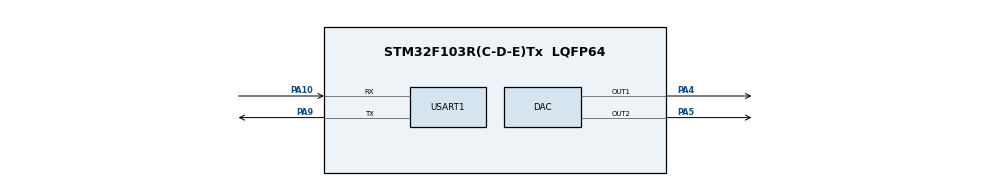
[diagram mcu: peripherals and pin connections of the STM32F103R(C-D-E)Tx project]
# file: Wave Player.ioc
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DAC.DAC_OutputBuffer=DAC_OUTPUTBUFFER_ENABLE
DAC.DAC_Trigger=DAC_TRIGGER_T2_TRGO
DAC.DAC_Trigger2=DAC_TRIGGER_T2_TRGO
Dma.DAC_CH1.0.Direction=DMA_MEMORY_TO_PERIPH
Dma.DAC_CH1.0.Instance=DMA2_Channel3
Dma.DAC_CH1.0.MemDataAlignment=DMA_MDATAALIGN_HALFWORD
Dma.DAC_CH1.0.MemInc=DMA_MINC_ENABLE
Dma.DAC_CH1.0.Mode=DMA_CIRCULAR
Dma.DAC_CH1.0.PeriphDataAlignment=DMA_PDATAALIGN_HALFWORD
Dma.DAC_CH1.0.PeriphInc=DMA_PINC_DISABLE
Dma.DAC_CH1.0.Priority=DMA_PRIORITY_MEDIUM
Dma.Request0=DAC_CH1
Mcu.Family=STM32F1
Mcu.Name=STM32F103R(C-D-E)Tx
Mcu.Package=LQFP64
NVIC.DMA2_Channel3_IRQn=true\:0\:0\:false\:false\:true\:false\:true
NVIC.PriorityGroup=NVIC_PRIORITYGROUP_4
PA10.Mode=Asynchronous
PA10.Signal=USART1_RX
PA13.Mode=JTAG_5_pins
PA13.Signal=SYS_JTMS-SWDIO
PA14.Mode=JTAG_5_pins
PA14.Signal=SYS_JTCK-SWCLK
PA15.Mode=JTAG_5_pins
PA15.Signal=SYS_JTDI
PA4.Signal=COMP_DAC1_group
PA5.Signal=COMP_DAC2_group
PA9.Mode=Asynchronous
PA9.Signal=USART1_TX
PB3.Mode=JTAG_5_pins
PB3.Signal=SYS_JTDO-TRACESWO
PB4.Mode=JTAG_5_pins
PB4.Signal=SYS_NJTRST
PD0-OSC_IN.Mode=HSE-External-Oscillator
PD0-OSC_IN.Signal=RCC_OSC_IN
PD1-OSC_OUT.Mode=HSE-External-Oscillator
PD1-OSC_OUT.Signal=RCC_OSC_OUT
ProjectManager.HeapSize=0x200
ProjectManager.StackSize=0x400
ProjectManager.TargetToolchain=MDK-ARM V5.27
RCC.AHBFreq_Value=72000000
RCC.APB1CLKDivider=RCC_HCLK_DIV2
RCC.APB1Freq_Value=36000000
RCC.APB1TimFreq_Value=72000000
RCC.APB2Freq_Value=72000000
RCC.APB2TimFreq_Value=72000000
RCC.HCLKFreq_Value=72000000
RCC.PLLMUL=RCC_PLL_MUL9
RCC.PLLSourceVirtual=RCC_PLLSOURCE_HSE
RCC.SYSCLKFreq_VALUE=72000000
RCC.SYSCLKSource=RCC_SYSCLKSOURCE_PLLCLK
RCC.USBFreq_Value=72000000
SH.COMP_DAC1_group.0=DAC_OUT1,DAC_OUT1
SH.COMP_DAC2_group.0=DAC_OUT2,DAC_OUT2
TIM2.Period=124
TIM2.Prescaler=7
TIM2.TIM_MasterOutputTrigger=TIM_TRGO_UPDATE
USART1.VirtualMode=VM_ASYNC
VP_TIM2_VS_ClockSourceINT.Mode=Internal
board=custom

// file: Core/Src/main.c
/* USER CODE BEGIN Header */
/**
  ******************************************************************************
  * @file           : main.c
  * @brief          : Main program body
  ******************************************************************************
  * @attention
  *
  * <h2><center>&copy; Copyright (c) 2022 STMicroelectronics.
  * All rights reserved.</center></h2>
  *
  * This software component is licensed by ST under BSD 3-Clause license,
  * the "License"; You may not use this file except in compliance with the
  * License. You may obtain a copy of the License at:
  *                        opensource.org/licenses/BSD-3-Clause
  *
  ******************************************************************************
  */
/* USER CODE END Header */
#include "main.h"

/* USER CODE BEGIN Includes */
#include "WAV_Handler.h"
/* USER CODE END Includes */

void SystemClock_Config(void);
static void MX_GPIO_Init(void);
static void MX_DMA_Init(void);
static void MX_DAC_Init(void);
static void MX_USART1_UART_Init(void);
static void MX_TIM2_Init(void);

int main(void)
{

  /* MCU Configuration--------------------------------------------------------*/

  /* Reset of all peripherals, Initializes the Flash interface and the Systick. */

  LL_APB2_GRP1_EnableClock(LL_APB2_GRP1_PERIPH_AFIO);
  LL_APB1_GRP1_EnableClock(LL_APB1_GRP1_PERIPH_PWR);

  NVIC_SetPriorityGrouping(NVIC_PRIORITYGROUP_4);

  /* System interrupt init*/

  /** ENABLE: Full SWJ (JTAG-DP + SW-DP): Reset State
  */
  LL_GPIO_AF_EnableRemap_SWJ();

  /* Configure the system clock */
  SystemClock_Config();

  /* Initialize all configured peripherals */
  MX_GPIO_Init();
  MX_DMA_Init();
  MX_DAC_Init();
  MX_USART1_UART_Init();
  MX_TIM2_Init();
  /* USER CODE BEGIN 2 */
	wave_Init();
	wave_play("Colors.wav");
  /* USER CODE END 2 */

  /* Infinite loop */
  while (1)
  {

  }
}

void SystemClock_Config(void)
{
  LL_FLASH_SetLatency(LL_FLASH_LATENCY_2);
  while(LL_FLASH_GetLatency()!= LL_FLASH_LATENCY_2)
  {
  }
  LL_RCC_HSE_Enable();

   /* Wait till HSE is ready */
  while(LL_RCC_HSE_IsReady() != 1)
  {

  }
  LL_RCC_PLL_ConfigDomain_SYS(LL_RCC_PLLSOURCE_HSE_DIV_1, LL_RCC_PLL_MUL_9);
  LL_RCC_PLL_Enable();

   /* Wait till PLL is ready */
  while(LL_RCC_PLL_IsReady() != 1)
  {

  }
  LL_RCC_SetAHBPrescaler(LL_RCC_SYSCLK_DIV_1);
  LL_RCC_SetAPB1Prescaler(LL_RCC_APB1_DIV_2);
  LL_RCC_SetAPB2Prescaler(LL_RCC_APB2_DIV_1);
  LL_RCC_SetSysClkSource(LL_RCC_SYS_CLKSOURCE_PLL);

   /* Wait till System clock is ready */
  while(LL_RCC_GetSysClkSource() != LL_RCC_SYS_CLKSOURCE_STATUS_PLL)
  {

  }
  LL_Init1msTick(72000000);
  LL_SetSystemCoreClock(72000000);
}

static void MX_DAC_Init(void)
{

  LL_DAC_InitTypeDef DAC_InitStruct = {0};

  LL_GPIO_InitTypeDef GPIO_InitStruct = {0};

  /* Peripheral clock enable */
  LL_APB1_GRP1_EnableClock(LL_APB1_GRP1_PERIPH_DAC1);

  LL_APB2_GRP1_EnableClock(LL_APB2_GRP1_PERIPH_GPIOA);
  /**DAC GPIO Configuration
  PA4   ------> DAC_OUT1
  PA5   ------> DAC_OUT2
  */
  GPIO_InitStruct.Pin = LL_GPIO_PIN_4|LL_GPIO_PIN_5;
  GPIO_InitStruct.Mode = LL_GPIO_MODE_ANALOG;
  LL_GPIO_Init(GPIOA, &GPIO_InitStruct);

  /* DAC DMA Init */

  /* DAC_CH1 Init */
  LL_DMA_SetDataTransferDirection(DMA2, LL_DMA_CHANNEL_3, LL_DMA_DIRECTION_MEMORY_TO_PERIPH);

  LL_DMA_SetChannelPriorityLevel(DMA2, LL_DMA_CHANNEL_3, LL_DMA_PRIORITY_MEDIUM);

  LL_DMA_SetMode(DMA2, LL_DMA_CHANNEL_3, LL_DMA_MODE_CIRCULAR);

  LL_DMA_SetPeriphIncMode(DMA2, LL_DMA_CHANNEL_3, LL_DMA_PERIPH_NOINCREMENT);

  LL_DMA_SetMemoryIncMode(DMA2, LL_DMA_CHANNEL_3, LL_DMA_MEMORY_INCREMENT);

  LL_DMA_SetPeriphSize(DMA2, LL_DMA_CHANNEL_3, LL_DMA_PDATAALIGN_HALFWORD);

  LL_DMA_SetMemorySize(DMA2, LL_DMA_CHANNEL_3, LL_DMA_MDATAALIGN_HALFWORD);

  /** DAC channel OUT1 config
  */
  DAC_InitStruct.TriggerSource = LL_DAC_TRIG_EXT_TIM2_TRGO;
  DAC_InitStruct.WaveAutoGeneration = LL_DAC_WAVE_AUTO_GENERATION_NONE;
  DAC_InitStruct.OutputBuffer = LL_DAC_OUTPUT_BUFFER_ENABLE;
  LL_DAC_Init(DAC, LL_DAC_CHANNEL_1, &DAC_InitStruct);
  LL_DAC_EnableTrigger(DAC, LL_DAC_CHANNEL_1);
  /** DAC channel OUT2 config
  */
  LL_DAC_Init(DAC, LL_DAC_CHANNEL_2, &DAC_InitStruct);
  LL_DAC_EnableTrigger(DAC, LL_DAC_CHANNEL_2);

}

static void MX_TIM2_Init(void)
{

  LL_TIM_InitTypeDef TIM_InitStruct = {0};

  /* Peripheral clock enable */
  LL_APB1_GRP1_EnableClock(LL_APB1_GRP1_PERIPH_TIM2);

  TIM_InitStruct.Prescaler = 7;
  TIM_InitStruct.CounterMode = LL_TIM_COUNTERMODE_UP;
  TIM_InitStruct.Autoreload = 124;
  TIM_InitStruct.ClockDivision = LL_TIM_CLOCKDIVISION_DIV1;
  LL_TIM_Init(TIM2, &TIM_InitStruct);
  LL_TIM_DisableARRPreload(TIM2);
  LL_TIM_SetClockSource(TIM2, LL_TIM_CLOCKSOURCE_INTERNAL);
  LL_TIM_SetTriggerOutput(TIM2, LL_TIM_TRGO_UPDATE);
  LL_TIM_DisableMasterSlaveMode(TIM2);

}

static void MX_USART1_UART_Init(void)
{

  LL_USART_InitTypeDef USART_InitStruct = {0};

  LL_GPIO_InitTypeDef GPIO_InitStruct = {0};

  /* Peripheral clock enable */
  LL_APB2_GRP1_EnableClock(LL_APB2_GRP1_PERIPH_USART1);

  LL_APB2_GRP1_EnableClock(LL_APB2_GRP1_PERIPH_GPIOA);
  /**USART1 GPIO Configuration
  PA9   ------> USART1_TX
  PA10   ------> USART1_RX
  */
  GPIO_InitStruct.Pin = LL_GPIO_PIN_9;
  GPIO_InitStruct.Mode = LL_GPIO_MODE_ALTERNATE;
  GPIO_InitStruct.Speed = LL_GPIO_SPEED_FREQ_HIGH;
  GPIO_InitStruct.OutputType = LL_GPIO_OUTPUT_PUSHPULL;
  LL_GPIO_Init(GPIOA, &GPIO_InitStruct);

  GPIO_InitStruct.Pin = LL_GPIO_PIN_10;
  GPIO_InitStruct.Mode = LL_GPIO_MODE_FLOATING;
  LL_GPIO_Init(GPIOA, &GPIO_InitStruct);

  USART_InitStruct.BaudRate = 115200;
  USART_InitStruct.DataWidth = LL_USART_DATAWIDTH_8B;
  USART_InitStruct.StopBits = LL_USART_STOPBITS_1;
  USART_InitStruct.Parity = LL_USART_PARITY_NONE;
  USART_InitStruct.TransferDirection = LL_USART_DIRECTION_TX_RX;
  USART_InitStruct.HardwareFlowControl = LL_USART_HWCONTROL_NONE;
  USART_InitStruct.OverSampling = LL_USART_OVERSAMPLING_16;
  LL_USART_Init(USART1, &USART_InitStruct);
  LL_USART_ConfigAsyncMode(USART1);
  LL_USART_Enable(USART1);

}

static void MX_DMA_Init(void)
{

  /* Init with LL driver */
  /* DMA controller clock enable */
  LL_AHB1_GRP1_EnableClock(LL_AHB1_GRP1_PERIPH_DMA2);

  /* DMA interrupt init */
  /* DMA2_Channel3_IRQn interrupt configuration */
  NVIC_SetPriority(DMA2_Channel3_IRQn, NVIC_EncodePriority(NVIC_GetPriorityGrouping(),0, 0));
  NVIC_EnableIRQ(DMA2_Channel3_IRQn);

}

static void MX_GPIO_Init(void)
{

  /* GPIO Ports Clock Enable */
  LL_APB2_GRP1_EnableClock(LL_APB2_GRP1_PERIPH_GPIOD);
  LL_APB2_GRP1_EnableClock(LL_APB2_GRP1_PERIPH_GPIOA);
  LL_APB2_GRP1_EnableClock(LL_APB2_GRP1_PERIPH_GPIOB);

}

void Error_Handler(void)
{
  __disable_irq();
  while (1)
  {
  }
}

/************************ (C) COPYRIGHT STMicroelectronics *****END OF FILE****/
